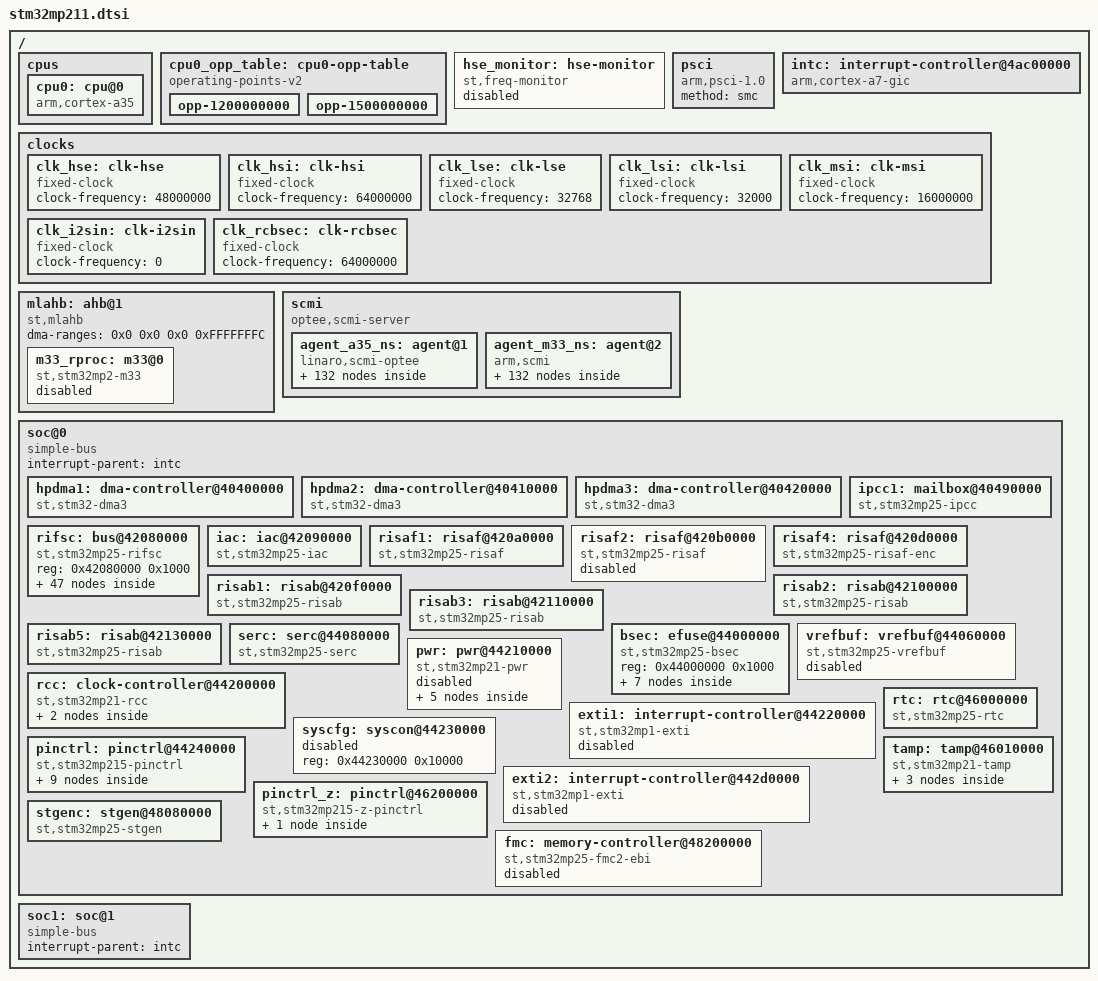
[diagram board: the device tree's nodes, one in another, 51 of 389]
// SPDX-License-Identifier: (GPL-2.0-only OR BSD-3-Clause)
/*
 * Copyright (C) 2024, STMicroelectronics - All Rights Reserved
 * Author: Alexandre Torgue <alexandre.torgue@foss.st.com> for STMicroelectronics.
 */
#include <dt-bindings/clock/st,stm32mp21-rcc.h>
#include <dt-bindings/gpio/gpio.h>
#include <dt-bindings/interrupt-controller/arm-gic.h>
#include <dt-bindings/regulator/st,stm32mp21-regulator.h>
#include <dt-bindings/reset/st,stm32mp21-rcc.h>
#include <dt-bindings/scmi/scmi-clock.h>
#include <dt-bindings/soc/stm32mp21-rifsc.h>
#include <dt-bindings/soc/stm32mp25-rif.h>
#include <dt-bindings/soc/stm32mp25-risab.h>
#include <dt-bindings/soc/stm32mp25-risaf.h>

/ {
	#address-cells = <2>;
	#size-cells = <2>;

	cpus {
		#address-cells = <1>;
		#size-cells = <0>;

		cpu0: cpu@0 {
			compatible = "arm,cortex-a35";
			device_type = "cpu";
			reg = <0>;
			enable-method = "psci";
			operating-points-v2 = <&cpu0_opp_table>;
			clocks = <&rcc CK_CPU1>;
		};
	};

	cpu0_opp_table: cpu0-opp-table {
		compatible = "operating-points-v2";

		opp-1200000000 {
			opp-hz = /bits/ 64 <1200000000>;
			opp-microvolt = <800000>;
			opp-supported-hw = <0x3>;
			st,opp-default;
		};

		opp-1500000000 {
			opp-hz = /bits/ 64 <1500000000>;
			opp-microvolt = <910000>;
			opp-supported-hw = <0x2>;
		};
	};

	hse_monitor: hse-monitor {
		compatible = "st,freq-monitor";
		counter = <&lptimer1 1 5 1 1>;
		clocks = <&rcc HSE_CK>, <&rcc HSI_CK>;
		clock-names = "hse", "hsi";
		status = "disabled";
	};

	psci {
		compatible = "arm,psci-1.0";
		method = "smc";
	};

	intc: interrupt-controller@4ac00000 {
		compatible = "arm,cortex-a7-gic";
		#interrupt-cells = <3>;
		interrupt-controller;
		reg = <0x0 0x4ac10000 0x0 0x1000>,
		      <0x0 0x4ac20000 0x0 0x2000>,
		      <0x0 0x4ac40000 0x0 0x2000>,
		      <0x0 0x4ac60000 0x0 0x2000>;
		#address-cells = <1>;
	};

	clocks {
		clk_hse: clk-hse {
			#clock-cells = <0>;
			compatible = "fixed-clock";
			clock-frequency = <48000000>;
		};

		clk_hsi: clk-hsi {
			#clock-cells = <0>;
			compatible = "fixed-clock";
			clock-frequency = <64000000>;
		};

		clk_lse: clk-lse {
			#clock-cells = <0>;
			compatible = "fixed-clock";
			clock-frequency = <32768>;
		};

		clk_lsi: clk-lsi {
			#clock-cells = <0>;
			compatible = "fixed-clock";
			clock-frequency = <32000>;
		};

		clk_msi: clk-msi {
			#clock-cells = <0>;
			compatible = "fixed-clock";
			clock-frequency = <16000000>;
		};

		clk_i2sin: clk-i2sin {
			#clock-cells = <0>;
			compatible = "fixed-clock";
			clock-frequency = <0>;
		};

		clk_rcbsec: clk-rcbsec {
			#clock-cells = <0>;
			compatible = "fixed-clock";
			clock-frequency = <64000000>;
		};
	};

	mlahb: ahb@1 {
		compatible = "st,mlahb", "simple-bus";
		#address-cells = <1>;
		#size-cells = <1>;
		ranges = <0x0 0x0 0x0 0xFFFFFFFC>;
		dma-ranges = <0x0 0x0 0x0 0xFFFFFFFC>;

		m33_rproc: m33@0 {
			compatible = "st,stm32mp2-m33";
			#reset-cells = <1>;
			reg = <0 0>;
			resets = <&rcc C2_R>,
				 <&rcc C2_HOLDBOOT_R>;
			reset-names = "mcu_rst", "hold_boot";
			status = "disabled";
		};
	};

	scmi: scmi {
		compatible = "optee,scmi-server";
		#address-cells = <1>;
		#size-cells = <0>;

		agent_a35_ns: agent@1 {
			reg = <1>;
			compatible = "linaro,scmi-optee";
			scmi-channel-id = <0>;
			#address-cells = <1>;
			#size-cells = <0>;

			scmi_clock: protocol@14 {
				reg = <0x14>;

				clocks {
					#address-cells = <1>;
					#size-cells = <0>;
					#clock-cells = <1>;

					clock@0 {
						reg = <CK_SCMI_ICN_HS_MCU>;
						clocks = <&rcc CK_ICN_HS_MCU>;
						domain-name = "ck_icn_hs_mcu";
						flags = <SCMI_CLOCK_DEFAULT_ENABLED>;
					};

					clock@1 {
						reg = <CK_SCMI_ICN_SDMMC>;
						clocks = <&rcc CK_ICN_SDMMC>;
						domain-name = "ck_icn_sdmmc";
						flags = <SCMI_CLOCK_DEFAULT_ENABLED>;
					};

					clock@2 {
						reg = <CK_SCMI_ICN_DDR>;
						clocks = <&rcc CK_ICN_DDR>;
						domain-name = "ck_icn_ddr";
						flags = <SCMI_CLOCK_DEFAULT_ENABLED>;
					};

					clock@3 {
						reg = <CK_SCMI_ICN_DISPLAY>;
						clocks = <&rcc CK_ICN_DISPLAY>;
						domain-name = "ck_icn_display";
						flags = <SCMI_CLOCK_DEFAULT_ENABLED>;
					};

					clock@4 {
						reg = <CK_SCMI_ICN_HSL>;
						clocks = <&rcc CK_ICN_HSL>;
						domain-name = "ck_icn_hsl";
						flags = <SCMI_CLOCK_DEFAULT_ENABLED>;
					};

					clock@5 {
						reg = <CK_SCMI_ICN_NIC>;
						clocks = <&rcc CK_ICN_NIC>;
						domain-name = "ck_icn_nic";
						flags = <SCMI_CLOCK_DEFAULT_ENABLED>;
					};

					clock@7 {
						reg = <CK_SCMI_FLEXGEN_07>;
						clocks = <&rcc CK_FLEXGEN_07>;
						domain-name = "ck_flexgen_07";
						flags = <SCMI_CLOCK_DEFAULT_ENABLED>;
					};

					clock@8 {
						reg = <CK_SCMI_FLEXGEN_08>;
						clocks = <&rcc CK_FLEXGEN_08>;
						domain-name = "ck_flexgen_08";
						flags = <SCMI_CLOCK_DEFAULT_ENABLED>;
					};

					clock@9 {
						reg = <CK_SCMI_FLEXGEN_09>;
						clocks = <&rcc CK_FLEXGEN_09>;
						domain-name = "ck_flexgen_09";
						flags = <SCMI_CLOCK_DEFAULT_ENABLED>;
					};

					clock@a {
						reg = <CK_SCMI_FLEXGEN_10>;
						clocks = <&rcc CK_FLEXGEN_10>;
						domain-name = "ck_flexgen_10";
						flags = <(SCMI_CLOCK_DEFAULT_ENABLED |
							  SCMI_CLOCK_ALLOW_SET_RATE)>;
					};

					clock@b {
						reg = <CK_SCMI_FLEXGEN_11>;
						clocks = <&rcc CK_FLEXGEN_11>;
						domain-name = "ck_flexgen_11";
						flags = <(SCMI_CLOCK_DEFAULT_ENABLED |
							  SCMI_CLOCK_ALLOW_SET_RATE)>;
					};

					clock@c {
						reg = <CK_SCMI_FLEXGEN_12>;
						clocks = <&rcc CK_FLEXGEN_12>;
						domain-name = "ck_flexgen_12";
						flags = <SCMI_CLOCK_DEFAULT_ENABLED>;
					};

					clock@d {
						reg = <CK_SCMI_FLEXGEN_13>;
						clocks = <&rcc CK_FLEXGEN_13>;
						domain-name = "ck_flexgen_13";
						flags = <SCMI_CLOCK_DEFAULT_ENABLED>;
					};

					clock@e {
						reg = <CK_SCMI_FLEXGEN_14>;
						clocks = <&rcc CK_FLEXGEN_14>;
						domain-name = "ck_flexgen_14";
						flags = <SCMI_CLOCK_DEFAULT_ENABLED>;
					};

					clock@f {
						reg = <CK_SCMI_FLEXGEN_15>;
						clocks = <&rcc CK_FLEXGEN_15>;
						domain-name = "ck_flexgen_15";
						flags = <SCMI_CLOCK_DEFAULT_ENABLED>;
					};

					clock@10 {
						reg = <CK_SCMI_FLEXGEN_16>;
						clocks = <&rcc CK_FLEXGEN_16>;
						domain-name = "ck_flexgen_16";
						flags = <(SCMI_CLOCK_DEFAULT_ENABLED |
							  SCMI_CLOCK_ALLOW_SET_RATE)>;
					};

					clock@11 {
						reg = <CK_SCMI_FLEXGEN_17>;
						clocks = <&rcc CK_FLEXGEN_17>;
						domain-name = "ck_flexgen_17";
						flags = <SCMI_CLOCK_DEFAULT_ENABLED>;
					};

					clock@12 {
						reg = <CK_SCMI_FLEXGEN_18>;
						clocks = <&rcc CK_FLEXGEN_18>;
						domain-name = "ck_flexgen_18";
						flags = <SCMI_CLOCK_DEFAULT_ENABLED>;
					};

					clock@13 {
						reg = <CK_SCMI_FLEXGEN_19>;
						clocks = <&rcc CK_FLEXGEN_19>;
						domain-name = "ck_flexgen_19";
						flags = <SCMI_CLOCK_DEFAULT_ENABLED>;
					};

					clock@14 {
						reg = <CK_SCMI_FLEXGEN_20>;
						clocks = <&rcc CK_FLEXGEN_20>;
						domain-name = "ck_flexgen_20";
						flags = <SCMI_CLOCK_DEFAULT_ENABLED>;
					};

					clock@15 {
						reg = <CK_SCMI_FLEXGEN_21>;
						clocks = <&rcc CK_FLEXGEN_21>;
						domain-name = "ck_flexgen_21";
						flags = <SCMI_CLOCK_DEFAULT_ENABLED>;
					};

					clock@16 {
						reg = <CK_SCMI_FLEXGEN_22>;
						clocks = <&rcc CK_FLEXGEN_22>;
						domain-name = "ck_flexgen_22";
						flags = <(SCMI_CLOCK_DEFAULT_ENABLED |
							  SCMI_CLOCK_ALLOW_SET_RATE)>;
					};

					clock@17 {
						reg = <CK_SCMI_FLEXGEN_23>;
						clocks = <&rcc CK_FLEXGEN_23>;
						domain-name = "ck_flexgen_23";
						flags = <(SCMI_CLOCK_DEFAULT_ENABLED |
							  SCMI_CLOCK_ALLOW_SET_RATE)>;
					};

					clock@18 {
						reg = <CK_SCMI_FLEXGEN_24>;
						clocks = <&rcc CK_FLEXGEN_24>;
						domain-name = "ck_flexgen_24";
						flags = <(SCMI_CLOCK_DEFAULT_ENABLED |
							  SCMI_CLOCK_ALLOW_SET_RATE)>;
					};

					clock@19 {
						reg = <CK_SCMI_FLEXGEN_25>;
						clocks = <&rcc CK_FLEXGEN_25>;
						domain-name = "ck_flexgen_25";
						flags = <(SCMI_CLOCK_DEFAULT_ENABLED |
							  SCMI_CLOCK_ALLOW_SET_RATE)>;
					};

					clock@1a {
						reg = <CK_SCMI_FLEXGEN_26>;
						clocks = <&rcc CK_FLEXGEN_26>;
						domain-name = "ck_flexgen_26";
						flags = <SCMI_CLOCK_DEFAULT_ENABLED>;
					};

					clock@1b {
						reg = <CK_SCMI_FLEXGEN_27>;
						clocks = <&rcc CK_FLEXGEN_27>;
						domain-name = "ck_flexgen_27";
						flags = <(SCMI_CLOCK_DEFAULT_ENABLED |
							  SCMI_CLOCK_ALLOW_SET_RATE)>;
					};

					clock@1c {
						reg = <CK_SCMI_FLEXGEN_28>;
						clocks = <&rcc CK_FLEXGEN_28>;
						domain-name = "ck_flexgen_28";
						flags = <SCMI_CLOCK_DEFAULT_ENABLED>;
					};

					clock@1d {
						reg = <CK_SCMI_FLEXGEN_29>;
						clocks = <&rcc CK_FLEXGEN_29>;
						domain-name = "ck_flexgen_29";
						flags = <SCMI_CLOCK_DEFAULT_ENABLED>;
					};

					clock@1e {
						reg = <CK_SCMI_FLEXGEN_30>;
						clocks = <&rcc CK_FLEXGEN_30>;
						domain-name = "ck_flexgen_30";
						flags = <SCMI_CLOCK_DEFAULT_ENABLED>;
					};

					clock@1f {
						reg = <CK_SCMI_FLEXGEN_31>;
						clocks = <&rcc CK_FLEXGEN_31>;
						domain-name = "ck_flexgen_31";
						flags = <SCMI_CLOCK_DEFAULT_ENABLED>;
					};

					clock@20 {
						reg = <CK_SCMI_FLEXGEN_32>;
						clocks = <&rcc CK_FLEXGEN_32>;
						domain-name = "ck_flexgen_32";
						flags = <SCMI_CLOCK_DEFAULT_ENABLED>;
					};

					clock@21 {
						reg = <CK_SCMI_FLEXGEN_33>;
						clocks = <&rcc CK_FLEXGEN_33>;
						domain-name = "ck_flexgen_33";
						flags = <SCMI_CLOCK_DEFAULT_ENABLED>;
					};

					clock@22 {
						reg = <CK_SCMI_FLEXGEN_34>;
						clocks = <&rcc CK_FLEXGEN_34>;
						domain-name = "ck_flexgen_34";
						flags = <SCMI_CLOCK_DEFAULT_ENABLED>;
					};

					clock@23 {
						reg = <CK_SCMI_FLEXGEN_35>;
						clocks = <&rcc CK_FLEXGEN_35>;
						domain-name = "ck_flexgen_35";
						flags = <SCMI_CLOCK_DEFAULT_ENABLED>;
					};

					clock@24 {
						reg = <CK_SCMI_FLEXGEN_36>;
						clocks = <&rcc CK_FLEXGEN_36>;
						domain-name = "ck_flexgen_36";
						flags = <SCMI_CLOCK_DEFAULT_ENABLED>;
					};

					clock@25 {
						reg = <CK_SCMI_FLEXGEN_37>;
						clocks = <&rcc CK_FLEXGEN_37>;
						domain-name = "ck_flexgen_37";
						flags = <SCMI_CLOCK_DEFAULT_ENABLED>;
					};

					clock@26 {
						reg = <CK_SCMI_FLEXGEN_38>;
						clocks = <&rcc CK_FLEXGEN_38>;
						domain-name = "ck_flexgen_38";
						flags = <SCMI_CLOCK_DEFAULT_ENABLED>;
					};

					clock@27 {
						reg = <CK_SCMI_FLEXGEN_39>;
						clocks = <&rcc CK_FLEXGEN_39>;
						domain-name = "ck_flexgen_39";
						flags = <SCMI_CLOCK_DEFAULT_ENABLED>;
					};

					clock@28 {
						reg = <CK_SCMI_FLEXGEN_40>;
						clocks = <&rcc CK_FLEXGEN_40>;
						domain-name = "ck_flexgen_40";
						flags = <SCMI_CLOCK_DEFAULT_ENABLED>;
					};

					clock@29 {
						reg = <CK_SCMI_FLEXGEN_41>;
						clocks = <&rcc CK_FLEXGEN_41>;
						domain-name = "ck_flexgen_41";
						flags = <SCMI_CLOCK_DEFAULT_ENABLED>;
					};

					clock@2a {
						reg = <CK_SCMI_FLEXGEN_42>;
						clocks = <&rcc CK_FLEXGEN_42>;
						domain-name = "ck_flexgen_42";
						flags = <SCMI_CLOCK_DEFAULT_ENABLED>;
					};

					clock@2b {
						reg = <CK_SCMI_FLEXGEN_43>;
						clocks = <&rcc CK_FLEXGEN_43>;
						domain-name = "ck_flexgen_43";
						flags = <SCMI_CLOCK_DEFAULT_ENABLED>;
					};

					clock@2c {
						reg = <CK_SCMI_FLEXGEN_44>;
						clocks = <&rcc CK_FLEXGEN_44>;
						domain-name = "ck_flexgen_44";
						flags = <SCMI_CLOCK_DEFAULT_ENABLED>;
					};

					clock@2d {
						reg = <CK_SCMI_FLEXGEN_45>;
						clocks = <&rcc CK_FLEXGEN_45>;
						domain-name = "ck_flexgen_45";
						flags = <SCMI_CLOCK_DEFAULT_ENABLED>;
					};

					clock@2e {
						reg = <CK_SCMI_FLEXGEN_46>;
						clocks = <&rcc CK_FLEXGEN_46>;
						domain-name = "ck_flexgen_46";
						flags = <SCMI_CLOCK_DEFAULT_ENABLED>;
					};

					clock@2f {
						reg = <CK_SCMI_FLEXGEN_47>;
						clocks = <&rcc CK_FLEXGEN_47>;
						domain-name = "ck_flexgen_47";
						flags = <SCMI_CLOCK_DEFAULT_ENABLED>;
					};

					clock@30 {
						reg = <CK_SCMI_FLEXGEN_48>;
						clocks = <&rcc CK_FLEXGEN_48>;
						domain-name = "ck_flexgen_48";
						flags = <SCMI_CLOCK_DEFAULT_ENABLED>;
					};

					clock@31 {
						reg = <CK_SCMI_FLEXGEN_49>;
						clocks = <&rcc CK_FLEXGEN_49>;
						domain-name = "ck_flexgen_49";
						flags = <SCMI_CLOCK_DEFAULT_ENABLED>;
					};

					clock@32 {
						reg = <CK_SCMI_FLEXGEN_50>;
						clocks = <&rcc CK_FLEXGEN_50>;
						domain-name = "ck_flexgen_50";
						flags = <SCMI_CLOCK_DEFAULT_ENABLED>;
					};

					clock@33 {
						reg = <CK_SCMI_FLEXGEN_51>;
						clocks = <&rcc CK_FLEXGEN_51>;
						domain-name = "ck_flexgen_51";
						flags = <SCMI_CLOCK_DEFAULT_ENABLED>;
					};

					clock@34 {
						reg = <CK_SCMI_FLEXGEN_52>;
						clocks = <&rcc CK_FLEXGEN_52>;
						domain-name = "ck_flexgen_52";
						flags = <SCMI_CLOCK_DEFAULT_ENABLED>;
					};

					clock@35 {
						reg = <CK_SCMI_FLEXGEN_53>;
						clocks = <&rcc CK_FLEXGEN_53>;
						domain-name = "ck_flexgen_53";
						flags = <SCMI_CLOCK_DEFAULT_ENABLED>;
					};

					clock@36 {
						reg = <CK_SCMI_FLEXGEN_54>;
						clocks = <&rcc CK_FLEXGEN_54>;
						domain-name = "ck_flexgen_54";
						flags = <SCMI_CLOCK_DEFAULT_ENABLED>;
					};

					clock@37 {
						reg = <CK_SCMI_FLEXGEN_55>;
						clocks = <&rcc CK_FLEXGEN_55>;
						domain-name = "ck_flexgen_55";
						flags = <SCMI_CLOCK_DEFAULT_ENABLED>;
					};

					clock@38 {
						reg = <CK_SCMI_FLEXGEN_56>;
						clocks = <&rcc CK_FLEXGEN_56>;
						domain-name = "ck_flexgen_56";
						flags = <SCMI_CLOCK_DEFAULT_ENABLED>;
					};

					clock@39 {
						reg = <CK_SCMI_FLEXGEN_57>;
						clocks = <&rcc CK_FLEXGEN_57>;
						domain-name = "ck_flexgen_57";
						flags = <SCMI_CLOCK_DEFAULT_ENABLED>;
					};

					clock@3a {
						reg = <CK_SCMI_FLEXGEN_58>;
						clocks = <&rcc CK_FLEXGEN_58>;
						domain-name = "ck_flexgen_58";
						flags = <SCMI_CLOCK_DEFAULT_ENABLED>;
					};

					clock@3b {
						reg = <CK_SCMI_FLEXGEN_59>;
						clocks = <&rcc CK_FLEXGEN_59>;
						domain-name = "ck_flexgen_59";
						flags = <SCMI_CLOCK_DEFAULT_ENABLED>;
					};

					clock@3c {
						reg = <CK_SCMI_FLEXGEN_60>;
						clocks = <&rcc CK_FLEXGEN_60>;
						domain-name = "ck_flexgen_60";
						flags = <SCMI_CLOCK_DEFAULT_ENABLED>;
					};

					clock@3d {
						reg = <CK_SCMI_FLEXGEN_61>;
						clocks = <&rcc CK_FLEXGEN_61>;
						domain-name = "ck_flexgen_61";
						flags = <SCMI_CLOCK_DEFAULT_ENABLED>;
					};

					clock@3e {
						reg = <CK_SCMI_FLEXGEN_62>;
						clocks = <&rcc CK_FLEXGEN_62>;
						domain-name = "ck_flexgen_62";
						flags = <SCMI_CLOCK_DEFAULT_ENABLED>;
					};

					clock@3f {
						reg = <CK_SCMI_FLEXGEN_63>;
						clocks = <&rcc CK_FLEXGEN_63>;
						domain-name = "ck_flexgen_63";
						flags = <SCMI_CLOCK_DEFAULT_ENABLED>;
					};

					clock@40 {
						reg = <CK_SCMI_ICN_LS_MCU>;
						clocks = <&rcc CK_ICN_LS_MCU>;
						domain-name = "ck_icn_ls_mcu";
						flags = <SCMI_CLOCK_DEFAULT_ENABLED>;
					};

					clock@41 {
						reg = <CK_SCMI_HSE>;
						clocks = <&rcc HSE_CK>;
						domain-name = "hse_ck";
						flags = <SCMI_CLOCK_DEFAULT_ENABLED>;
					};

					clock@42 {
						reg = <CK_SCMI_LSE>;
						clocks = <&rcc LSE_CK>;
						domain-name = "lse_ck";
						flags = <SCMI_CLOCK_DEFAULT_ENABLED>;
					};

					clock@43 {
						reg = <CK_SCMI_HSI>;
						clocks = <&rcc HSI_CK>;
						domain-name = "hsi_ck";
						flags = <SCMI_CLOCK_DEFAULT_ENABLED>;
					};

					clock@44 {
						reg = <CK_SCMI_LSI>;
						clocks = <&rcc LSI_CK>;
						domain-name = "lsi_ck";
						flags = <SCMI_CLOCK_DEFAULT_ENABLED>;
					};

					clock@45 {
						reg = <CK_SCMI_MSI>;
						clocks = <&rcc MSI_CK>;
						domain-name = "msi_ck";
						flags = <SCMI_CLOCK_DEFAULT_ENABLED>;
					};

					clock@46 {
						reg = <CK_SCMI_HSE_DIV2>;
						clocks = <&rcc HSE_DIV2_CK>;
						domain-name = "hse_div2_ck";
					};

					clock@47 {
						reg = <CK_SCMI_CPU1>;
						clocks = <&rcc CK_CPU1>;
						domain-name = "ck_cpu1";
						flags = <SCMI_CLOCK_DEFAULT_ENABLED>;
					};

					clock@48 {
						reg = <CK_SCMI_SYSCPU1>;
						clocks = <&rcc CK_BUS_SYSCPU1>;
						domain-name = "ck_bus_syscpu1";
						flags = <SCMI_CLOCK_DEFAULT_ENABLED>;
					};

					clock@49 {
						reg = <CK_SCMI_PLL2>;
						clocks = <&rcc PLL2_CK>;
						domain-name = "ck_pll2";
						flags = <SCMI_CLOCK_DEFAULT_ENABLED>;
					};

					clock@4a {
						reg = <CK_SCMI_RTC>;
						clocks = <&rcc CK_BUS_RTC>;
						domain-name = "ck_bus_rtc";
						flags = <SCMI_CLOCK_DEFAULT_ENABLED>;
					};

					clock@4b {
						reg = <CK_SCMI_RTCCK>;
						clocks = <&rcc RTC_CK>;
						domain-name = "rtc_ck";
						flags = <SCMI_CLOCK_DEFAULT_ENABLED>;
					};

					clock@4c {
						reg = <CK_SCMI_ICN_APB1>;
						clocks = <&rcc CK_ICN_APB1>;
						domain-name = "ck_icn_apb1";
						flags = <SCMI_CLOCK_DEFAULT_ENABLED>;
					};

					clock@4d {
						reg = <CK_SCMI_ICN_APB2>;
						clocks = <&rcc CK_ICN_APB2>;
						domain-name = "ck_icn_apb2";
						flags = <SCMI_CLOCK_DEFAULT_ENABLED>;
					};

					clock@4e {
						reg = <CK_SCMI_ICN_APB3>;
						clocks = <&rcc CK_ICN_APB3>;
						domain-name = "ck_icn_apb3";
						flags = <SCMI_CLOCK_DEFAULT_ENABLED>;
					};

					clock@4f {
						reg = <CK_SCMI_ICN_APB4>;
						clocks = <&rcc CK_ICN_APB4>;
						domain-name = "ck_icn_apb4";
						flags = <SCMI_CLOCK_DEFAULT_ENABLED>;
					};

					clock@50 {
						reg = <CK_SCMI_ICN_APB5>;
						clocks = <&rcc CK_ICN_APB5>;
						domain-name = "ck_icn_apb5";
						flags = <SCMI_CLOCK_DEFAULT_ENABLED>;
					};

					clock@51 {
						reg = <CK_SCMI_ICN_APBDBG>;
						clocks = <&rcc CK_ICN_APBDBG>;
						domain-name = "ck_icn_apbdbg";
						flags = <SCMI_CLOCK_DEFAULT_ENABLED>;
					};

					clock@52 {
						reg = <CK_SCMI_TIMG1>;
						clocks = <&rcc TIMG1_CK>;
						domain-name = "timg1_ck";
						flags = <SCMI_CLOCK_DEFAULT_ENABLED>;
					};

					clock@53 {
						reg = <CK_SCMI_TIMG2>;
						clocks = <&rcc TIMG2_CK>;
						domain-name = "timg2_ck";
						flags = <SCMI_CLOCK_DEFAULT_ENABLED>;
					};

					clock@54 {
						reg = <CK_SCMI_BKPSRAM>;
						clocks = <&rcc CK_BUS_BKPSRAM>;
						domain-name = "ck_bus_bkpsram";
						flags = <SCMI_CLOCK_DEFAULT_ENABLED>;
					};

					clock@55 {
						reg = <CK_SCMI_BSEC>;
						clocks = <&rcc CK_BUS_BSEC>;
						domain-name = "ck_bus_bsec";
						flags = <SCMI_CLOCK_DEFAULT_ENABLED>;
					};

					clock@56 {
						reg = <CK_SCMI_BUS_ETR>;
						clocks = <&rcc CK_BUS_ETR>;
						domain-name = "ck_icn_p_etr";
						flags = <SCMI_CLOCK_DEFAULT_ENABLED>;
					};

					clock@57 {
						reg = <CK_SCMI_FMC>;
						clocks = <&rcc CK_KER_FMC>;
						domain-name = "ck_ker_fmc";
						flags = <SCMI_CLOCK_DEFAULT_ENABLED>;
					};

					clock@58 {
						reg = <CK_SCMI_GPIOA>;
						clocks = <&rcc CK_BUS_GPIOA>;
						domain-name = "ck_bus_gpioa";
						flags = <SCMI_CLOCK_DEFAULT_ENABLED>;
					};

					clock@59 {
						reg = <CK_SCMI_GPIOB>;
						clocks = <&rcc CK_BUS_GPIOB>;
						domain-name = "ck_bus_gpiob";
						flags = <SCMI_CLOCK_DEFAULT_ENABLED>;
					};

					clock@5a {
						reg = <CK_SCMI_GPIOC>;
						clocks = <&rcc CK_BUS_GPIOC>;
						domain-name = "ck_bus_gpioc";
						flags = <SCMI_CLOCK_DEFAULT_ENABLED>;
					};

					clock@5b {
						reg = <CK_SCMI_GPIOD>;
						clocks = <&rcc CK_BUS_GPIOD>;
						domain-name = "ck_bus_gpiod";
						flags = <SCMI_CLOCK_DEFAULT_ENABLED>;
					};

					clock@5c {
						reg = <CK_SCMI_GPIOE>;
						clocks = <&rcc CK_BUS_GPIOE>;
						domain-name = "ck_bus_gpioe";
						flags = <SCMI_CLOCK_DEFAULT_ENABLED>;
					};

					clock@5d {
						reg = <CK_SCMI_GPIOF>;
						clocks = <&rcc CK_BUS_GPIOF>;
						domain-name = "ck_bus_gpiof";
						flags = <SCMI_CLOCK_DEFAULT_ENABLED>;
					};

					clock@5e {
						reg = <CK_SCMI_GPIOG>;
						clocks = <&rcc CK_BUS_GPIOG>;
						domain-name = "ck_bus_gpiog";
						flags = <SCMI_CLOCK_DEFAULT_ENABLED>;
					};

					clock@5f {
						reg = <CK_SCMI_GPIOH>;
						clocks = <&rcc CK_BUS_GPIOH>;
						domain-name = "ck_bus_gpioh";
						flags = <SCMI_CLOCK_DEFAULT_ENABLED>;
					};

					clock@60 {
						reg = <CK_SCMI_GPIOI>;
						clocks = <&rcc CK_BUS_GPIOI>;
						domain-name = "ck_bus_gpioi";
						flags = <SCMI_CLOCK_DEFAULT_ENABLED>;
					};

					clock@61 {
						reg = <CK_SCMI_GPIOZ>;
						clocks = <&rcc CK_BUS_GPIOZ>;
						domain-name = "ck_bus_gpioz";
						flags = <SCMI_CLOCK_DEFAULT_ENABLED>;
					};

					clock@62 {
						reg = <CK_SCMI_HPDMA1>;
						clocks = <&rcc CK_BUS_HPDMA1>;
						domain-name = "ck_bus_hpdma1";
						flags = <SCMI_CLOCK_DEFAULT_ENABLED>;
					};

					clock@63 {
						reg = <CK_SCMI_HPDMA2>;
						clocks = <&rcc CK_BUS_HPDMA2>;
						domain-name = "ck_bus_hpdma2";
						flags = <SCMI_CLOCK_DEFAULT_ENABLED>;
					};

					clock@64 {
						reg = <CK_SCMI_HPDMA3>;
						clocks = <&rcc CK_BUS_HPDMA3>;
						domain-name = "ck_bus_hpdma3";
						flags = <SCMI_CLOCK_DEFAULT_ENABLED>;
					};

					clock@65 {
						reg = <CK_SCMI_IPCC1>;
						clocks = <&rcc CK_BUS_IPCC1>;
						domain-name = "ck_bus_ipcc1";
						flags = <SCMI_CLOCK_DEFAULT_ENABLED>;
					};

					clock@66 {
						reg = <CK_SCMI_RETRAM>;
						clocks = <&rcc CK_BUS_RETRAM>;
						domain-name = "ck_bus_retram";
						flags = <SCMI_CLOCK_DEFAULT_ENABLED>;
					};

					clock@67 {
						reg = <CK_SCMI_SRAM1>;
						clocks = <&rcc CK_BUS_SRAM1>;
						domain-name = "ck_bus_sram1";
						flags = <SCMI_CLOCK_DEFAULT_ENABLED>;
					};

					clock@68 {
						reg = <CK_SCMI_SYSRAM>;
						clocks = <&rcc CK_BUS_SYSRAM>;
						domain-name = "ck_icn_s_sysram";
						flags = <SCMI_CLOCK_DEFAULT_ENABLED>;
					};

					clock@69 {
						reg = <CK_SCMI_OSPI1>;
						clocks = <&rcc CK_KER_OSPI1>;
						domain-name = "ck_ker_ospi1";
						flags = <SCMI_CLOCK_DEFAULT_ENABLED>;
					};

					clock@6a {
						reg = <CK_SCMI_TPIU>;
						clocks = <&rcc CK_KER_TPIU>;
						domain-name = "ck_ker_tpiu";
						flags = <SCMI_CLOCK_DEFAULT_ENABLED>;
					};

					clock@6b {
						reg = <CK_SCMI_SYSDBG>;
						clocks = <&rcc CK_SYSDBG>;
						domain-name = "ck_sys_dbg";
						flags = <SCMI_CLOCK_DEFAULT_ENABLED>;
					};

					clock@6c {
						reg = <CK_SCMI_SYSATB>;
						clocks = <&rcc CK_BUS_SYSATB>;
						domain-name = "ck_sys_atb";
						flags = <SCMI_CLOCK_DEFAULT_ENABLED>;
					};

					clock@6d {
						reg = <CK_SCMI_TSDBG>;
						clocks = <&rcc CK_KER_TSDBG>;
						domain-name = "ck_ker_tsdbg";
						flags = <SCMI_CLOCK_DEFAULT_ENABLED>;
					};

					clock@6e {
						reg = <CK_SCMI_BUS_STM>;
						clocks = <&rcc CK_BUS_STM>;
						domain-name = "ck_icn_p_stm";
						flags = <SCMI_CLOCK_DEFAULT_ENABLED>;
					};

					clock@6f {
						reg = <CK_SCMI_KER_STM>;
						clocks = <&rcc CK_KER_STM>;
						domain-name = "ck_icn_s_stm";
						flags = <SCMI_CLOCK_DEFAULT_ENABLED>;
					};

					clock@70 {
						reg = <CK_SCMI_KER_ETR>;
						clocks = <&rcc CK_KER_ETR>;
						domain-name = "ck_icn_m_etr";
						flags = <SCMI_CLOCK_DEFAULT_ENABLED>;
					};

					clock@71 {
						reg = <CK_SCMI_HSI_KER_CK>;
						domain-name = "hsi_ker_ck";
						clocks = <&rcc HSI_KER_CK>;
						flags = <SCMI_CLOCK_DEFAULT_ENABLED>;
					};

					clock@72 {
						reg = <CK_SCMI_HSE_KER_CK>;
						domain-name = "hse_ker_ck";
						clocks = <&rcc HSE_KER_CK>;
						flags = <SCMI_CLOCK_DEFAULT_ENABLED>;
					};

					clock@73 {
						reg = <CK_SCMI_MSI_KER_CK>;
						domain-name = "msi_ker_ck";
						clocks = <&rcc MSI_KER_CK>;
						flags = <SCMI_CLOCK_DEFAULT_ENABLED>;
					};
				};
			};

			scmi_reset: protocol@16 {
				reg = <0x16>;

				resets {
					#address-cells = <1>;
					#size-cells = <0>;
					#reset-cells = <1>;

					reset@0 {
						reg = <RST_SCMI_C1_R>;
						domain-name = "c1";
						resets = <&rcc C1_R>;
					};

					reset@1 {
						reg = <RST_SCMI_C2_R>;
						domain-name = "c2";
						resets = <&m33_rproc 0>;
					};

					reset@2 {
						reg = <RST_SCMI_C1_HOLDBOOT_R>;
						domain-name = "c1_holdboot";
						resets = <&rcc C1_HOLDBOOT_R>;
					};

					reset@3 {
						reg = <RST_SCMI_C2_HOLDBOOT_R>;
						domain-name = "c2_holdboot";
						resets = <&m33_rproc 1>;
					};

					reset@4 {
						reg = <RST_SCMI_FMC>;
						domain-name = "fmc";
						resets = <&rcc FMC_R>;
					};

					reset@5 {
						reg = <RST_SCMI_OSPI1>;
						domain-name = "ospi1";
						resets = <&rcc OSPI1_R>;
					};

					reset@6 {
						reg = <RST_SCMI_OSPI1DLL>;
						domain-name = "ospi1_ddl";
						resets = <&rcc OSPI1DLL_R>;
					};
				};
			};

			scmi_regulator: protocol@17 {
				reg = <0x17>;

				scmi_regu: regulators {
					#address-cells = <1>;
					#size-cells = <0>;

					voltd-vddio1 {
						reg = <VOLTD_SCMI_VDDIO1>;
						voltd-supply = <&vddio1>;
					};

					voltd-vddio2 {
						reg = <VOLTD_SCMI_VDDIO2>;
						voltd-supply = <&vddio2>;
					};

					voltd-vddio3 {
						reg = <VOLTD_SCMI_VDDIO3>;
						voltd-supply = <&vddio3>;
					};

					voltd-vdda18adc {
						reg = <VOLTD_SCMI_ADC>;
						voltd-supply = <&vdda18adc>;
					};
				};
			};
		};

		agent_m33_ns: agent@2 {
			reg = <2>;
			compatible = "arm,scmi";
			scmi-channel-id = <0>;
			mbox-names = "scmi_cm33";
			mboxes = <&ipcc1 RIF_IPCC_CPU1_CHANNEL(16)>;
			shmem = <&ipc_shmem>;
			#address-cells = <1>;
			#size-cells = <0>;

			scmi_clock_m33: protocol@14 {
				reg = <0x14>;

				clocks {
					#address-cells = <1>;
					#size-cells = <0>;
					#clock-cells = <1>;

					clock@0 {
						reg = <CK_SCMI_ICN_HS_MCU>;
						clocks = <&rcc CK_ICN_HS_MCU>;
						domain-name = "ck_icn_hs_mcu";
						flags = <SCMI_CLOCK_DEFAULT_ENABLED>;
					};

					clock@1 {
						reg = <CK_SCMI_ICN_SDMMC>;
						clocks = <&rcc CK_ICN_SDMMC>;
						domain-name = "ck_icn_sdmmc";
						flags = <SCMI_CLOCK_DEFAULT_ENABLED>;
					};

					clock@2 {
						reg = <CK_SCMI_ICN_DDR>;
						clocks = <&rcc CK_ICN_DDR>;
						domain-name = "ck_icn_ddr";
						flags = <SCMI_CLOCK_DEFAULT_ENABLED>;
					};

					clock@3 {
						reg = <CK_SCMI_ICN_DISPLAY>;
						clocks = <&rcc CK_ICN_DISPLAY>;
						domain-name = "ck_icn_display";
						flags = <SCMI_CLOCK_DEFAULT_ENABLED>;
					};

					clock@4 {
						reg = <CK_SCMI_ICN_HSL>;
						clocks = <&rcc CK_ICN_HSL>;
						domain-name = "ck_icn_hsl";
						flags = <SCMI_CLOCK_DEFAULT_ENABLED>;
					};

					clock@5 {
						reg = <CK_SCMI_ICN_NIC>;
						clocks = <&rcc CK_ICN_NIC>;
						domain-name = "ck_icn_nic";
						flags = <SCMI_CLOCK_DEFAULT_ENABLED>;
					};

					clock@7 {
						reg = <CK_SCMI_FLEXGEN_07>;
						clocks = <&rcc CK_FLEXGEN_07>;
						domain-name = "ck_flexgen_07";
						flags = <SCMI_CLOCK_DEFAULT_ENABLED>;
					};

					clock@8 {
						reg = <CK_SCMI_FLEXGEN_08>;
						clocks = <&rcc CK_FLEXGEN_08>;
						domain-name = "ck_flexgen_08";
						flags = <SCMI_CLOCK_DEFAULT_ENABLED>;
					};

					clock@9 {
						reg = <CK_SCMI_FLEXGEN_09>;
						clocks = <&rcc CK_FLEXGEN_09>;
						domain-name = "ck_flexgen_09";
						flags = <SCMI_CLOCK_DEFAULT_ENABLED>;
					};

					clock@a {
						reg = <CK_SCMI_FLEXGEN_10>;
						clocks = <&rcc CK_FLEXGEN_10>;
						domain-name = "ck_flexgen_10";
						flags = <(SCMI_CLOCK_DEFAULT_ENABLED |
							  SCMI_CLOCK_ALLOW_SET_RATE)>;
					};

					clock@b {
						reg = <CK_SCMI_FLEXGEN_11>;
						clocks = <&rcc CK_FLEXGEN_11>;
						domain-name = "ck_flexgen_11";
						flags = <(SCMI_CLOCK_DEFAULT_ENABLED |
							  SCMI_CLOCK_ALLOW_SET_RATE)>;
					};

					clock@c {
						reg = <CK_SCMI_FLEXGEN_12>;
						clocks = <&rcc CK_FLEXGEN_12>;
						domain-name = "ck_flexgen_12";
						flags = <SCMI_CLOCK_DEFAULT_ENABLED>;
					};

					clock@d {
						reg = <CK_SCMI_FLEXGEN_13>;
						clocks = <&rcc CK_FLEXGEN_13>;
						domain-name = "ck_flexgen_13";
						flags = <SCMI_CLOCK_DEFAULT_ENABLED>;
					};

					clock@e {
						reg = <CK_SCMI_FLEXGEN_14>;
						clocks = <&rcc CK_FLEXGEN_14>;
						domain-name = "ck_flexgen_14";
						flags = <SCMI_CLOCK_DEFAULT_ENABLED>;
					};

					clock@f {
						reg = <CK_SCMI_FLEXGEN_15>;
						clocks = <&rcc CK_FLEXGEN_15>;
						domain-name = "ck_flexgen_15";
						flags = <SCMI_CLOCK_DEFAULT_ENABLED>;
					};

					clock@10 {
						reg = <CK_SCMI_FLEXGEN_16>;
						clocks = <&rcc CK_FLEXGEN_16>;
						domain-name = "ck_flexgen_16";
						flags = <(SCMI_CLOCK_DEFAULT_ENABLED |
							  SCMI_CLOCK_ALLOW_SET_RATE)>;
					};

					clock@11 {
						reg = <CK_SCMI_FLEXGEN_17>;
						clocks = <&rcc CK_FLEXGEN_17>;
						domain-name = "ck_flexgen_17";
						flags = <SCMI_CLOCK_DEFAULT_ENABLED>;
					};

					clock@12 {
						reg = <CK_SCMI_FLEXGEN_18>;
						clocks = <&rcc CK_FLEXGEN_18>;
						domain-name = "ck_flexgen_18";
						flags = <SCMI_CLOCK_DEFAULT_ENABLED>;
					};

					clock@13 {
						reg = <CK_SCMI_FLEXGEN_19>;
						clocks = <&rcc CK_FLEXGEN_19>;
						domain-name = "ck_flexgen_19";
						flags = <SCMI_CLOCK_DEFAULT_ENABLED>;
					};

					clock@14 {
						reg = <CK_SCMI_FLEXGEN_20>;
						clocks = <&rcc CK_FLEXGEN_20>;
						domain-name = "ck_flexgen_20";
						flags = <SCMI_CLOCK_DEFAULT_ENABLED>;
					};

					clock@15 {
						reg = <CK_SCMI_FLEXGEN_21>;
						clocks = <&rcc CK_FLEXGEN_21>;
						domain-name = "ck_flexgen_21";
						flags = <SCMI_CLOCK_DEFAULT_ENABLED>;
					};

					clock@16 {
						reg = <CK_SCMI_FLEXGEN_22>;
						clocks = <&rcc CK_FLEXGEN_22>;
						domain-name = "ck_flexgen_22";
						flags = <(SCMI_CLOCK_DEFAULT_ENABLED |
							  SCMI_CLOCK_ALLOW_SET_RATE)>;
					};

					clock@17 {
						reg = <CK_SCMI_FLEXGEN_23>;
						clocks = <&rcc CK_FLEXGEN_23>;
						domain-name = "ck_flexgen_23";
						flags = <(SCMI_CLOCK_DEFAULT_ENABLED |
							  SCMI_CLOCK_ALLOW_SET_RATE)>;
					};

					clock@18 {
						reg = <CK_SCMI_FLEXGEN_24>;
						clocks = <&rcc CK_FLEXGEN_24>;
						domain-name = "ck_flexgen_24";
						flags = <(SCMI_CLOCK_DEFAULT_ENABLED |
							  SCMI_CLOCK_ALLOW_SET_RATE)>;
					};

					clock@19 {
						reg = <CK_SCMI_FLEXGEN_25>;
						clocks = <&rcc CK_FLEXGEN_25>;
						domain-name = "ck_flexgen_25";
						flags = <(SCMI_CLOCK_DEFAULT_ENABLED |
							  SCMI_CLOCK_ALLOW_SET_RATE)>;
					};

					clock@1a {
						reg = <CK_SCMI_FLEXGEN_26>;
						clocks = <&rcc CK_FLEXGEN_26>;
						domain-name = "ck_flexgen_26";
						flags = <SCMI_CLOCK_DEFAULT_ENABLED>;
					};

					clock@1b {
						reg = <CK_SCMI_FLEXGEN_27>;
						clocks = <&rcc CK_FLEXGEN_27>;
						domain-name = "ck_flexgen_27";
						flags = <(SCMI_CLOCK_DEFAULT_ENABLED |
							  SCMI_CLOCK_ALLOW_SET_RATE)>;
					};

					clock@1c {
						reg = <CK_SCMI_FLEXGEN_28>;
						clocks = <&rcc CK_FLEXGEN_28>;
						domain-name = "ck_flexgen_28";
						flags = <SCMI_CLOCK_DEFAULT_ENABLED>;
					};

					clock@1d {
						reg = <CK_SCMI_FLEXGEN_29>;
						clocks = <&rcc CK_FLEXGEN_29>;
						domain-name = "ck_flexgen_29";
						flags = <SCMI_CLOCK_DEFAULT_ENABLED>;
					};

					clock@1e {
						reg = <CK_SCMI_FLEXGEN_30>;
						clocks = <&rcc CK_FLEXGEN_30>;
						domain-name = "ck_flexgen_30";
						flags = <SCMI_CLOCK_DEFAULT_ENABLED>;
					};

					clock@1f {
						reg = <CK_SCMI_FLEXGEN_31>;
						clocks = <&rcc CK_FLEXGEN_31>;
						domain-name = "ck_flexgen_31";
						flags = <SCMI_CLOCK_DEFAULT_ENABLED>;
					};

					clock@20 {
						reg = <CK_SCMI_FLEXGEN_32>;
						clocks = <&rcc CK_FLEXGEN_32>;
						domain-name = "ck_flexgen_32";
						flags = <SCMI_CLOCK_DEFAULT_ENABLED>;
					};

					clock@21 {
						reg = <CK_SCMI_FLEXGEN_33>;
						clocks = <&rcc CK_FLEXGEN_33>;
						domain-name = "ck_flexgen_33";
						flags = <SCMI_CLOCK_DEFAULT_ENABLED>;
					};

					clock@22 {
						reg = <CK_SCMI_FLEXGEN_34>;
						clocks = <&rcc CK_FLEXGEN_34>;
						domain-name = "ck_flexgen_34";
						flags = <SCMI_CLOCK_DEFAULT_ENABLED>;
					};

					clock@23 {
						reg = <CK_SCMI_FLEXGEN_35>;
						clocks = <&rcc CK_FLEXGEN_35>;
						domain-name = "ck_flexgen_35";
						flags = <SCMI_CLOCK_DEFAULT_ENABLED>;
					};

					clock@24 {
						reg = <CK_SCMI_FLEXGEN_36>;
						clocks = <&rcc CK_FLEXGEN_36>;
						domain-name = "ck_flexgen_36";
						flags = <SCMI_CLOCK_DEFAULT_ENABLED>;
					};

					clock@25 {
						reg = <CK_SCMI_FLEXGEN_37>;
						clocks = <&rcc CK_FLEXGEN_37>;
						domain-name = "ck_flexgen_37";
						flags = <SCMI_CLOCK_DEFAULT_ENABLED>;
					};

					clock@26 {
						reg = <CK_SCMI_FLEXGEN_38>;
						clocks = <&rcc CK_FLEXGEN_38>;
						domain-name = "ck_flexgen_38";
						flags = <SCMI_CLOCK_DEFAULT_ENABLED>;
					};

					clock@27 {
						reg = <CK_SCMI_FLEXGEN_39>;
						clocks = <&rcc CK_FLEXGEN_39>;
						domain-name = "ck_flexgen_39";
						flags = <SCMI_CLOCK_DEFAULT_ENABLED>;
					};

					clock@28 {
						reg = <CK_SCMI_FLEXGEN_40>;
						clocks = <&rcc CK_FLEXGEN_40>;
						domain-name = "ck_flexgen_40";
						flags = <SCMI_CLOCK_DEFAULT_ENABLED>;
					};

					clock@29 {
						reg = <CK_SCMI_FLEXGEN_41>;
						clocks = <&rcc CK_FLEXGEN_41>;
						domain-name = "ck_flexgen_41";
						flags = <SCMI_CLOCK_DEFAULT_ENABLED>;
					};

					clock@2a {
						reg = <CK_SCMI_FLEXGEN_42>;
						clocks = <&rcc CK_FLEXGEN_42>;
						domain-name = "ck_flexgen_42";
						flags = <SCMI_CLOCK_DEFAULT_ENABLED>;
					};

					clock@2b {
						reg = <CK_SCMI_FLEXGEN_43>;
						clocks = <&rcc CK_FLEXGEN_43>;
						domain-name = "ck_flexgen_43";
						flags = <SCMI_CLOCK_DEFAULT_ENABLED>;
					};

					clock@2c {
						reg = <CK_SCMI_FLEXGEN_44>;
						clocks = <&rcc CK_FLEXGEN_44>;
						domain-name = "ck_flexgen_44";
						flags = <SCMI_CLOCK_DEFAULT_ENABLED>;
					};

					clock@2d {
						reg = <CK_SCMI_FLEXGEN_45>;
						clocks = <&rcc CK_FLEXGEN_45>;
						domain-name = "ck_flexgen_45";
						flags = <SCMI_CLOCK_DEFAULT_ENABLED>;
					};

					clock@2e {
						reg = <CK_SCMI_FLEXGEN_46>;
						clocks = <&rcc CK_FLEXGEN_46>;
						domain-name = "ck_flexgen_46";
						flags = <SCMI_CLOCK_DEFAULT_ENABLED>;
					};

					clock@2f {
						reg = <CK_SCMI_FLEXGEN_47>;
						clocks = <&rcc CK_FLEXGEN_47>;
						domain-name = "ck_flexgen_47";
						flags = <SCMI_CLOCK_DEFAULT_ENABLED>;
					};

					clock@30 {
						reg = <CK_SCMI_FLEXGEN_48>;
						clocks = <&rcc CK_FLEXGEN_48>;
						domain-name = "ck_flexgen_48";
						flags = <SCMI_CLOCK_DEFAULT_ENABLED>;
					};

					clock@31 {
						reg = <CK_SCMI_FLEXGEN_49>;
						clocks = <&rcc CK_FLEXGEN_49>;
						domain-name = "ck_flexgen_49";
						flags = <SCMI_CLOCK_DEFAULT_ENABLED>;
					};

					clock@32 {
						reg = <CK_SCMI_FLEXGEN_50>;
						clocks = <&rcc CK_FLEXGEN_50>;
						domain-name = "ck_flexgen_50";
						flags = <SCMI_CLOCK_DEFAULT_ENABLED>;
					};

					clock@33 {
						reg = <CK_SCMI_FLEXGEN_51>;
						clocks = <&rcc CK_FLEXGEN_51>;
						domain-name = "ck_flexgen_51";
						flags = <SCMI_CLOCK_DEFAULT_ENABLED>;
					};

					clock@34 {
						reg = <CK_SCMI_FLEXGEN_52>;
						clocks = <&rcc CK_FLEXGEN_52>;
						domain-name = "ck_flexgen_52";
						flags = <SCMI_CLOCK_DEFAULT_ENABLED>;
					};

					clock@35 {
						reg = <CK_SCMI_FLEXGEN_53>;
						clocks = <&rcc CK_FLEXGEN_53>;
						domain-name = "ck_flexgen_53";
						flags = <SCMI_CLOCK_DEFAULT_ENABLED>;
					};

					clock@36 {
						reg = <CK_SCMI_FLEXGEN_54>;
						clocks = <&rcc CK_FLEXGEN_54>;
						domain-name = "ck_flexgen_54";
						flags = <SCMI_CLOCK_DEFAULT_ENABLED>;
					};

					clock@37 {
						reg = <CK_SCMI_FLEXGEN_55>;
						clocks = <&rcc CK_FLEXGEN_55>;
						domain-name = "ck_flexgen_55";
						flags = <SCMI_CLOCK_DEFAULT_ENABLED>;
					};

					clock@38 {
						reg = <CK_SCMI_FLEXGEN_56>;
						clocks = <&rcc CK_FLEXGEN_56>;
						domain-name = "ck_flexgen_56";
						flags = <SCMI_CLOCK_DEFAULT_ENABLED>;
					};

					clock@39 {
						reg = <CK_SCMI_FLEXGEN_57>;
						clocks = <&rcc CK_FLEXGEN_57>;
						domain-name = "ck_flexgen_57";
						flags = <SCMI_CLOCK_DEFAULT_ENABLED>;
					};

					clock@3a {
						reg = <CK_SCMI_FLEXGEN_58>;
						clocks = <&rcc CK_FLEXGEN_58>;
						domain-name = "ck_flexgen_58";
						flags = <SCMI_CLOCK_DEFAULT_ENABLED>;
					};

					clock@3b {
						reg = <CK_SCMI_FLEXGEN_59>;
						clocks = <&rcc CK_FLEXGEN_59>;
						domain-name = "ck_flexgen_59";
						flags = <SCMI_CLOCK_DEFAULT_ENABLED>;
					};

					clock@3c {
						reg = <CK_SCMI_FLEXGEN_60>;
						clocks = <&rcc CK_FLEXGEN_60>;
						domain-name = "ck_flexgen_60";
						flags = <SCMI_CLOCK_DEFAULT_ENABLED>;
					};

					clock@3d {
						reg = <CK_SCMI_FLEXGEN_61>;
						clocks = <&rcc CK_FLEXGEN_61>;
						domain-name = "ck_flexgen_61";
						flags = <SCMI_CLOCK_DEFAULT_ENABLED>;
					};

					clock@3e {
						reg = <CK_SCMI_FLEXGEN_62>;
						clocks = <&rcc CK_FLEXGEN_62>;
						domain-name = "ck_flexgen_62";
						flags = <SCMI_CLOCK_DEFAULT_ENABLED>;
					};

					clock@3f {
						reg = <CK_SCMI_FLEXGEN_63>;
						clocks = <&rcc CK_FLEXGEN_63>;
						domain-name = "ck_flexgen_63";
						flags = <SCMI_CLOCK_DEFAULT_ENABLED>;
					};

					clock@40 {
						reg = <CK_SCMI_ICN_LS_MCU>;
						clocks = <&rcc CK_ICN_LS_MCU>;
						domain-name = "ck_icn_ls_mcu";
						flags = <SCMI_CLOCK_DEFAULT_ENABLED>;
					};

					clock@41 {
						reg = <CK_SCMI_HSE>;
						clocks = <&rcc HSE_CK>;
						domain-name = "hse_ck";
						flags = <SCMI_CLOCK_DEFAULT_ENABLED>;
					};

					clock@42 {
						reg = <CK_SCMI_LSE>;
						clocks = <&rcc LSE_CK>;
						domain-name = "lse_ck";
						flags = <SCMI_CLOCK_DEFAULT_ENABLED>;
					};

					clock@43 {
						reg = <CK_SCMI_HSI>;
						clocks = <&rcc HSI_CK>;
						domain-name = "hsi_ck";
						flags = <SCMI_CLOCK_DEFAULT_ENABLED>;
					};

					clock@44 {
						reg = <CK_SCMI_LSI>;
						clocks = <&rcc LSI_CK>;
						domain-name = "lsi_ck";
						flags = <SCMI_CLOCK_DEFAULT_ENABLED>;
					};

					clock@45 {
						reg = <CK_SCMI_MSI>;
						clocks = <&rcc MSI_CK>;
						domain-name = "msi_ck";
						flags = <SCMI_CLOCK_DEFAULT_ENABLED>;
					};

					clock@46 {
						reg = <CK_SCMI_HSE_DIV2>;
						clocks = <&rcc HSE_DIV2_CK>;
						domain-name = "hse_div2_ck";
					};

					clock@47 {
						reg = <CK_SCMI_CPU1>;
						clocks = <&rcc CK_CPU1>;
						domain-name = "ck_cpu1";
						flags = <SCMI_CLOCK_DEFAULT_ENABLED>;
					};

					clock@48 {
						reg = <CK_SCMI_SYSCPU1>;
						clocks = <&rcc CK_BUS_SYSCPU1>;
						domain-name = "ck_bus_syscpu1";
						flags = <SCMI_CLOCK_DEFAULT_ENABLED>;
					};

					clock@49 {
						reg = <CK_SCMI_PLL2>;
						clocks = <&rcc PLL2_CK>;
						domain-name = "ck_pll2";
						flags = <SCMI_CLOCK_DEFAULT_ENABLED>;
					};

					clock@4a {
						reg = <CK_SCMI_RTC>;
						clocks = <&rcc CK_BUS_RTC>;
						domain-name = "ck_bus_rtc";
						flags = <SCMI_CLOCK_DEFAULT_ENABLED>;
					};

					clock@4b {
						reg = <CK_SCMI_RTCCK>;
						clocks = <&rcc RTC_CK>;
						domain-name = "rtc_ck";
						flags = <SCMI_CLOCK_DEFAULT_ENABLED>;
					};

					clock@4c {
						reg = <CK_SCMI_ICN_APB1>;
						clocks = <&rcc CK_ICN_APB1>;
						domain-name = "ck_icn_apb1";
						flags = <SCMI_CLOCK_DEFAULT_ENABLED>;
					};

					clock@4d {
						reg = <CK_SCMI_ICN_APB2>;
						clocks = <&rcc CK_ICN_APB2>;
						domain-name = "ck_icn_apb2";
						flags = <SCMI_CLOCK_DEFAULT_ENABLED>;
					};

					clock@4e {
						reg = <CK_SCMI_ICN_APB3>;
						clocks = <&rcc CK_ICN_APB3>;
						domain-name = "ck_icn_apb3";
						flags = <SCMI_CLOCK_DEFAULT_ENABLED>;
					};

					clock@4f {
						reg = <CK_SCMI_ICN_APB4>;
						clocks = <&rcc CK_ICN_APB4>;
						domain-name = "ck_icn_apb4";
						flags = <SCMI_CLOCK_DEFAULT_ENABLED>;
					};

					clock@50 {
						reg = <CK_SCMI_ICN_APB5>;
						clocks = <&rcc CK_ICN_APB5>;
						domain-name = "ck_icn_apb5";
						flags = <SCMI_CLOCK_DEFAULT_ENABLED>;
					};

					clock@51 {
						reg = <CK_SCMI_ICN_APBDBG>;
						clocks = <&rcc CK_ICN_APBDBG>;
						domain-name = "ck_icn_apbdbg";
						flags = <SCMI_CLOCK_DEFAULT_ENABLED>;
					};

					clock@52 {
						reg = <CK_SCMI_TIMG1>;
						clocks = <&rcc TIMG1_CK>;
						domain-name = "timg1_ck";
						flags = <SCMI_CLOCK_DEFAULT_ENABLED>;
					};

					clock@53 {
						reg = <CK_SCMI_TIMG2>;
						clocks = <&rcc TIMG2_CK>;
						domain-name = "timg2_ck";
						flags = <SCMI_CLOCK_DEFAULT_ENABLED>;
					};

					clock@54 {
						reg = <CK_SCMI_BKPSRAM>;
						clocks = <&rcc CK_BUS_BKPSRAM>;
						domain-name = "ck_bus_bkpsram";
						flags = <SCMI_CLOCK_DEFAULT_ENABLED>;
					};

					clock@55 {
						reg = <CK_SCMI_BSEC>;
						clocks = <&rcc CK_BUS_BSEC>;
						domain-name = "ck_bus_bsec";
						flags = <SCMI_CLOCK_DEFAULT_ENABLED>;
					};

					clock@56 {
						reg = <CK_SCMI_BUS_ETR>;
						clocks = <&rcc CK_BUS_ETR>;
						domain-name = "ck_icn_p_etr";
						flags = <SCMI_CLOCK_DEFAULT_ENABLED>;
					};

					clock@57 {
						reg = <CK_SCMI_FMC>;
						clocks = <&rcc CK_KER_FMC>;
						domain-name = "ck_ker_fmc";
						flags = <SCMI_CLOCK_DEFAULT_ENABLED>;
					};

					clock@58 {
						reg = <CK_SCMI_GPIOA>;
						clocks = <&rcc CK_BUS_GPIOA>;
						domain-name = "ck_bus_gpioa";
						flags = <SCMI_CLOCK_DEFAULT_ENABLED>;
					};

					clock@59 {
						reg = <CK_SCMI_GPIOB>;
						clocks = <&rcc CK_BUS_GPIOB>;
						domain-name = "ck_bus_gpiob";
						flags = <SCMI_CLOCK_DEFAULT_ENABLED>;
					};

					clock@5a {
						reg = <CK_SCMI_GPIOC>;
						clocks = <&rcc CK_BUS_GPIOC>;
						domain-name = "ck_bus_gpioc";
						flags = <SCMI_CLOCK_DEFAULT_ENABLED>;
					};

					clock@5b {
						reg = <CK_SCMI_GPIOD>;
						clocks = <&rcc CK_BUS_GPIOD>;
						domain-name = "ck_bus_gpiod";
						flags = <SCMI_CLOCK_DEFAULT_ENABLED>;
					};

					clock@5c {
						reg = <CK_SCMI_GPIOE>;
						clocks = <&rcc CK_BUS_GPIOE>;
						domain-name = "ck_bus_gpioe";
						flags = <SCMI_CLOCK_DEFAULT_ENABLED>;
					};

					clock@5d {
						reg = <CK_SCMI_GPIOF>;
						clocks = <&rcc CK_BUS_GPIOF>;
						domain-name = "ck_bus_gpiof";
						flags = <SCMI_CLOCK_DEFAULT_ENABLED>;
					};

					clock@5e {
						reg = <CK_SCMI_GPIOG>;
						clocks = <&rcc CK_BUS_GPIOG>;
						domain-name = "ck_bus_gpiog";
						flags = <SCMI_CLOCK_DEFAULT_ENABLED>;
					};

					clock@5f {
						reg = <CK_SCMI_GPIOH>;
						clocks = <&rcc CK_BUS_GPIOH>;
						domain-name = "ck_bus_gpioh";
						flags = <SCMI_CLOCK_DEFAULT_ENABLED>;
					};

					clock@60 {
						reg = <CK_SCMI_GPIOI>;
						clocks = <&rcc CK_BUS_GPIOI>;
						domain-name = "ck_bus_gpioi";
						flags = <SCMI_CLOCK_DEFAULT_ENABLED>;
					};

					clock@61 {
						reg = <CK_SCMI_GPIOZ>;
						clocks = <&rcc CK_BUS_GPIOZ>;
						domain-name = "ck_bus_gpioz";
						flags = <SCMI_CLOCK_DEFAULT_ENABLED>;
					};

					clock@62 {
						reg = <CK_SCMI_HPDMA1>;
						clocks = <&rcc CK_BUS_HPDMA1>;
						domain-name = "ck_bus_hpdma1";
						flags = <SCMI_CLOCK_DEFAULT_ENABLED>;
					};

					clock@63 {
						reg = <CK_SCMI_HPDMA2>;
						clocks = <&rcc CK_BUS_HPDMA2>;
						domain-name = "ck_bus_hpdma2";
						flags = <SCMI_CLOCK_DEFAULT_ENABLED>;
					};

					clock@64 {
						reg = <CK_SCMI_HPDMA3>;
						clocks = <&rcc CK_BUS_HPDMA3>;
						domain-name = "ck_bus_hpdma3";
						flags = <SCMI_CLOCK_DEFAULT_ENABLED>;
					};

					clock@65 {
						reg = <CK_SCMI_IPCC1>;
						clocks = <&rcc CK_BUS_IPCC1>;
						domain-name = "ck_bus_ipcc1";
						flags = <SCMI_CLOCK_DEFAULT_ENABLED>;
					};

					clock@66 {
						reg = <CK_SCMI_RETRAM>;
						clocks = <&rcc CK_BUS_RETRAM>;
						domain-name = "ck_bus_retram";
						flags = <SCMI_CLOCK_DEFAULT_ENABLED>;
					};

					clock@67 {
						reg = <CK_SCMI_SRAM1>;
						clocks = <&rcc CK_BUS_SRAM1>;
						domain-name = "ck_bus_sram1";
						flags = <SCMI_CLOCK_DEFAULT_ENABLED>;
					};

					clock@68 {
						reg = <CK_SCMI_SYSRAM>;
						clocks = <&rcc CK_BUS_SYSRAM>;
						domain-name = "ck_icn_s_sysram";
						flags = <SCMI_CLOCK_DEFAULT_ENABLED>;
					};

					clock@69 {
						reg = <CK_SCMI_OSPI1>;
						clocks = <&rcc CK_KER_OSPI1>;
						domain-name = "ck_ker_ospi1";
						flags = <SCMI_CLOCK_DEFAULT_ENABLED>;
					};

					clock@6a {
						reg = <CK_SCMI_TPIU>;
						clocks = <&rcc CK_KER_TPIU>;
						domain-name = "ck_ker_tpiu";
						flags = <SCMI_CLOCK_DEFAULT_ENABLED>;
					};

					clock@6b {
						reg = <CK_SCMI_SYSDBG>;
						clocks = <&rcc CK_SYSDBG>;
						domain-name = "ck_sys_dbg";
						flags = <SCMI_CLOCK_DEFAULT_ENABLED>;
					};

					clock@6c {
						reg = <CK_SCMI_SYSATB>;
						clocks = <&rcc CK_BUS_SYSATB>;
						domain-name = "ck_sys_atb";
						flags = <SCMI_CLOCK_DEFAULT_ENABLED>;
					};

					clock@6d {
						reg = <CK_SCMI_TSDBG>;
						clocks = <&rcc CK_KER_TSDBG>;
						domain-name = "ck_ker_tsdbg";
						flags = <SCMI_CLOCK_DEFAULT_ENABLED>;
					};

					clock@6e {
						reg = <CK_SCMI_BUS_STM>;
						clocks = <&rcc CK_BUS_STM>;
						domain-name = "ck_icn_p_stm";
						flags = <SCMI_CLOCK_DEFAULT_ENABLED>;
					};

					clock@6f {
						reg = <CK_SCMI_KER_STM>;
						clocks = <&rcc CK_KER_STM>;
						domain-name = "ck_icn_s_stm";
						flags = <SCMI_CLOCK_DEFAULT_ENABLED>;
					};

					clock@70 {
						reg = <CK_SCMI_KER_ETR>;
						clocks = <&rcc CK_KER_ETR>;
						domain-name = "ck_icn_m_etr";
						flags = <SCMI_CLOCK_DEFAULT_ENABLED>;
					};

					clock@71 {
						reg = <CK_SCMI_HSI_KER_CK>;
						domain-name = "hsi_ker_ck";
						clocks = <&rcc HSI_KER_CK>;
						flags = <SCMI_CLOCK_DEFAULT_ENABLED>;
					};

					clock@72 {
						reg = <CK_SCMI_HSE_KER_CK>;
						domain-name = "hse_ker_ck";
						clocks = <&rcc HSE_KER_CK>;
						flags = <SCMI_CLOCK_DEFAULT_ENABLED>;
					};

					clock@73 {
						reg = <CK_SCMI_MSI_KER_CK>;
						domain-name = "msi_ker_ck";
						clocks = <&rcc MSI_KER_CK>;
						flags = <SCMI_CLOCK_DEFAULT_ENABLED>;
					};
				};
			};

			scmi_reset_m33: protocol@16 {
				reg = <0x16>;

				resets {
					#address-cells = <1>;
					#size-cells = <0>;
					#reset-cells = <1>;

					reset@0 {
						reg = <RST_SCMI_C1_R>;
						domain-name = "c1";
						resets = <&rcc C1_R>;
					};

					reset@1 {
						reg = <RST_SCMI_C2_R>;
						domain-name = "c2";
						resets = <&m33_rproc 0>;
					};

					reset@2 {
						reg = <RST_SCMI_C1_HOLDBOOT_R>;
						domain-name = "c1_holdboot";
						resets = <&rcc C1_HOLDBOOT_R>;
					};

					reset@3 {
						reg = <RST_SCMI_C2_HOLDBOOT_R>;
						domain-name = "c2_holdboot";
						resets = <&m33_rproc 1>;
					};

					reset@4 {
						reg = <RST_SCMI_FMC>;
						domain-name = "fmc";
						resets = <&rcc FMC_R>;
					};

					reset@5 {
						reg = <RST_SCMI_OSPI1>;
						domain-name = "ospi1";
						resets = <&rcc OSPI1_R>;
					};

					reset@6 {
						reg = <RST_SCMI_OSPI1DLL>;
						domain-name = "ospi1_ddl";
						resets = <&rcc OSPI1DLL_R>;
					};
				};
			};

			scmi_regulator_m33: protocol@17 {
				reg = <0x17>;

				regulators {
					#address-cells = <1>;
					#size-cells = <0>;

					voltd-vddio1 {
						reg = <VOLTD_SCMI_VDDIO1>;
						voltd-supply = <&vddio1>;
					};

					voltd-vddio2 {
						reg = <VOLTD_SCMI_VDDIO2>;
						voltd-supply = <&vddio2>;
					};

					voltd-vddio3 {
						reg = <VOLTD_SCMI_VDDIO3>;
						voltd-supply = <&vddio3>;
					};

					voltd-vdda18adc {
						reg = <VOLTD_SCMI_ADC>;
						voltd-supply = <&vdda18adc>;
					};
				};
			};
		};
	};

	soc@0 {
		compatible = "simple-bus";
		#address-cells = <1>;
		#size-cells = <1>;
		interrupt-parent = <&intc>;
		ranges = <0x0 0x0 0x0 0x80000000>;

		hpdma1: dma-controller@40400000 {
			compatible = "st,stm32-dma3";
			reg = <0x40400000 0x1000>;
			clocks = <&rcc CK_BUS_HPDMA1>;
			resets = <&rcc HPDMA1_R>;
			#dma-cells = <4>;
			st,syscfg-arcr = <&syscfg 0x2050 0x1>;
		};

		hpdma2: dma-controller@40410000 {
			compatible = "st,stm32-dma3";
			reg = <0x40410000 0x1000>;
			clocks = <&rcc CK_BUS_HPDMA2>;
			resets = <&rcc HPDMA2_R>;
			#dma-cells = <4>;
			st,syscfg-arcr = <&syscfg 0x2050 0x2>;
		};

		hpdma3: dma-controller@40420000 {
			compatible = "st,stm32-dma3";
			reg = <0x40420000 0x1000>;
			clocks = <&rcc CK_BUS_HPDMA3>;
			resets = <&rcc HPDMA3_R>;
			#dma-cells = <4>;
			st,syscfg-arcr = <&syscfg 0x2050 0x4>;
		};

		ipcc1: mailbox@40490000 {
			compatible = "st,stm32mp25-ipcc";
			reg = <0x40490000 0x400>;
			interrupts = <GIC_SPI 154 IRQ_TYPE_LEVEL_HIGH>;
			interrupt-names = "rx";
			clocks = <&rcc CK_BUS_IPCC1>;
		};

		rifsc: bus@42080000 {
			compatible = "st,stm32mp25-rifsc", "simple-bus";
			reg = <0x42080000 0x1000>;
			#address-cells = <1>;
			#size-cells = <1>;
			#access-controller-cells = <1>;

			lptimer1: timer@40090000 {
				compatible = "st,stm32mp21-lptimer";
				reg = <0x40090000 0x400>;
				interrupts = <GIC_SPI 149 IRQ_TYPE_LEVEL_HIGH>;
				clocks = <&rcc CK_KER_LPTIM1>;
				clock-names = "mux";
				#address-cells = <1>;
				#size-cells = <0>;
				access-controllers = <&rifsc STM32MP21_RIFSC_LPTIM1_ID>;
				status = "disabled";

				counter {
					compatible = "st,stm32mp21-lptimer-counter";
					status = "disabled";
				};

				pwm {
					compatible = "st,stm32mp21-pwm-lp";
					#pwm-cells = <3>;
					status = "disabled";
				};

				timer {
					compatible = "st,stm32mp21-lptimer-timer";
					status = "disabled";
				};

				trigger@0 {
					compatible = "st,stm32mp21-lptimer-trigger";
					reg = <0>;
					status = "disabled";
				};
			};

			lptimer2: timer@400a0000 {
				compatible = "st,stm32mp21-lptimer";
				reg = <0x400a0000 0x400>;
				interrupts = <GIC_SPI 180 IRQ_TYPE_LEVEL_HIGH>;
				clocks = <&rcc CK_KER_LPTIM2>;
				clock-names = "mux";
				#address-cells = <1>;
				#size-cells = <0>;
				status = "disabled";

				counter {
					compatible = "st,stm32mp21-lptimer-counter";
					status = "disabled";
				};

				pwm {
					compatible = "st,stm32mp21-pwm-lp";
					#pwm-cells = <3>;
					status = "disabled";
				};

				timer {
					compatible = "st,stm32mp21-lptimer-timer";
					status = "disabled";
				};

				trigger@1 {
					compatible = "st,stm32mp21-lptimer-trigger";
					reg = <1>;
					status = "disabled";
				};
			};

			usart2: serial@400e0000 {
				compatible = "st,stm32h7-uart";
				reg = <0x400e0000 0x400>;
				interrupts = <GIC_SPI 102 IRQ_TYPE_LEVEL_HIGH>;
				clocks = <&rcc CK_KER_USART2>;
				access-controllers = <&rifsc STM32MP21_RIFSC_USART2_ID>;
				status = "disabled";
			};

			usart3: serial@400f0000 {
				compatible = "st,stm32h7-uart";
				reg = <0x400f0000 0x400>;
				interrupts = <GIC_SPI 103 IRQ_TYPE_LEVEL_HIGH>;
				clocks = <&rcc CK_KER_USART3>;
				access-controllers = <&rifsc STM32MP21_RIFSC_USART3_ID>;
				status = "disabled";
			};

			uart4: serial@40100000 {
				compatible = "st,stm32h7-uart";
				reg = <0x40100000 0x400>;
				interrupts = <GIC_SPI 113 IRQ_TYPE_LEVEL_HIGH>;
				clocks = <&rcc CK_KER_UART4>;
				access-controllers = <&rifsc STM32MP21_RIFSC_UART4_ID>;
				status = "disabled";
			};

			uart5: serial@40110000 {
				compatible = "st,stm32h7-uart";
				reg = <0x40110000 0x400>;
				interrupts = <GIC_SPI 114 IRQ_TYPE_LEVEL_HIGH>;
				clocks = <&rcc CK_KER_UART5>;
				access-controllers = <&rifsc STM32MP21_RIFSC_UART5_ID>;
				status = "disabled";
			};

			i2c1: i2c@40170000 {
				compatible = "st,stm32mp25-i2c";
				reg = <0x40170000 0x400>;
				clocks = <&rcc CK_KER_I2C1>;
				resets = <&rcc I2C1_R>;
				#address-cells = <1>;
				#size-cells = <0>;
				i2c-analog-filter;
				access-controllers = <&rifsc STM32MP21_RIFSC_I2C1_ID>;
				status = "disabled";
			};

			i2c2: i2c@40180000 {
				compatible = "st,stm32mp25-i2c";
				reg = <0x40180000 0x400>;
				clocks = <&rcc CK_KER_I2C1>;
				resets = <&rcc I2C1_R>;
				#address-cells = <1>;
				#size-cells = <0>;
				i2c-analog-filter;
				access-controllers = <&rifsc STM32MP21_RIFSC_I2C2_ID>;
				status = "disabled";
			};

			usart6: serial@40220000 {
				compatible = "st,stm32h7-uart";
				reg = <0x40220000 0x400>;
				interrupts = <GIC_SPI 123 IRQ_TYPE_LEVEL_HIGH>;
				clocks = <&rcc CK_KER_USART6>;
				access-controllers = <&rifsc STM32MP21_RIFSC_USART6_ID>;
				status = "disabled";
			};

			usart1: serial@40330000 {
				compatible = "st,stm32h7-uart";
				reg = <0x40330000 0x400>;
				interrupts = <GIC_SPI 101 IRQ_TYPE_LEVEL_HIGH>;
				clocks = <&rcc CK_KER_USART1>;
				access-controllers = <&rifsc STM32MP21_RIFSC_USART1_ID>;
				status = "disabled";
			};

			uart7: serial@40370000 {
				compatible = "st,stm32h7-uart";
				reg = <0x40370000 0x400>;
				interrupts = <GIC_SPI 135 IRQ_TYPE_LEVEL_HIGH>;
				clocks = <&rcc CK_KER_UART7>;
				access-controllers = <&rifsc STM32MP21_RIFSC_UART7_ID>;
				status = "disabled";
			};

			adc_1: adc@404e0000 {
				compatible = "st,stm32mp21-adc-core";
				reg = <0x404e0000 0x400>;
				interrupts = <GIC_SPI 81 IRQ_TYPE_LEVEL_HIGH>;
				clocks = <&rcc CK_KER_ADC1>;
				clock-names = "adc";
				interrupt-controller;
				#interrupt-cells = <1>;
				#address-cells = <1>;
				#size-cells = <0>;
				access-controllers = <&rifsc STM32MP21_RIFSC_ADC1_ID>;
				status = "disabled";

				adc1: adc@0 {
					compatible = "st,stm32mp21-adc";
					#io-channel-cells = <1>;
					#address-cells = <1>;
					#size-cells = <0>;
					reg = <0x0>;
					interrupt-parent = <&adc_1>;
					interrupts = <0>;
					status = "disabled";

					channel@14 {
						reg = <14>;
						label = "vrefint";
					};
				};
			};

			adc_2: adc@404f0000 {
				compatible = "st,stm32mp21-adc-core";
				reg = <0x404f0000 0x400>;
				interrupts = <GIC_SPI 82 IRQ_TYPE_LEVEL_HIGH>;
				clocks = <&rcc CK_KER_ADC2>;
				clock-names = "adc";
				interrupt-controller;
				#interrupt-cells = <1>;
				#address-cells = <1>;
				#size-cells = <0>;
				access-controllers = <&rifsc STM32MP21_RIFSC_ADC2_ID>;
				status = "disabled";

				adc2: adc@0 {
					compatible = "st,stm32mp21-adc";
					#io-channel-cells = <1>;
					#address-cells = <1>;
					#size-cells = <0>;
					reg = <0x0>;
					interrupt-parent = <&adc_2>;
					interrupts = <0>;
					status = "disabled";

					channel@14 {
						reg = <14>;
						label = "vrefint";
					};
					channel@15 {
						reg = <15>;
						label = "vddcore";
					};
					channel@17 {
						reg = <17>;
						label = "vddcpu";
					};
				};
			};

			hash2: hash@42010000  {
				compatible = "st,stm32mp13-hash";
				reg = <0x42010000  0x400>;
				interrupts = <GIC_SPI 178 IRQ_TYPE_LEVEL_HIGH>;
				clocks = <&rcc CK_BUS_HASH2>;
				resets = <&rcc HASH2_R>;
				access-controllers = <&rifsc STM32MP21_RIFSC_HASH2_ID>;
				status = "disabled";
			};

			rng2: rng@42020000 {
				compatible = "st,stm32mp21-rng";
				reg = <0x42020000 0x400>;
				clocks = <&clk_rcbsec>, <&rcc CK_BUS_RNG2>;
				clock-names = "rng_clk", "rng_hclk";
				access-controllers = <&rifsc STM32MP21_RIFSC_RNG2_ID>;
				resets = <&rcc RNG2_R>;
			};

			iwdg1: watchdog@44010000 {
				compatible = "st,stm32mp1-iwdg";
				reg = <0x44010000 0x400>;
				interrupts = <GIC_SPI 2 IRQ_TYPE_LEVEL_HIGH>;
				clocks = <&rcc CK_BUS_IWDG1>, <&rcc LSI_CK>;
				clock-names = "pclk", "lsi";
				access-controllers = <&rifsc STM32MP21_RIFSC_IWDG1_ID>;
				status = "disabled";
			};

			iwdg2: watchdog@44020000 {
				compatible = "st,stm32mp1-iwdg";
				reg = <0x44020000 0x400>;
				interrupts = <GIC_SPI 3 IRQ_TYPE_LEVEL_HIGH>;
				clocks = <&rcc CK_BUS_IWDG2>, <&rcc LSI_CK>;
				clock-names = "pclk", "lsi";
				resets = <&rcc IWDG2_SYS_R>;
				access-controllers = <&rifsc STM32MP21_RIFSC_IWDG2_ID>;
				status = "disabled";
			};

			i2c3: i2c@46040000 {
				compatible = "st,stm32mp25-i2c";
				reg = <0x46040000 0x400>;
				clocks = <&rcc CK_KER_I2C3>;
				resets = <&rcc I2C3_R>;
				i2c-analog-filter;
				#address-cells = <1>;
				#size-cells = <0>;
				access-controllers = <&rifsc STM32MP21_RIFSC_I2C3_ID>;
				status = "disabled";
			};

			lptimer3: timer@46050000 {
				compatible = "st,stm32mp21-lptimer";
				reg = <0x46050000 0x400>;
				interrupts = <GIC_SPI 181 IRQ_TYPE_LEVEL_HIGH>;
				clocks = <&rcc CK_KER_LPTIM3>;
				clock-names = "mux";
				#address-cells = <1>;
				#size-cells = <0>;
				status = "disabled";

				counter {
					compatible = "st,stm32mp21-lptimer-counter";
					status = "disabled";
				};

				pwm {
					compatible = "st,stm32mp21-pwm-lp";
					#pwm-cells = <3>;
					status = "disabled";
				};

				timer {
					compatible = "st,stm32mp21-lptimer-timer";
					status = "disabled";
				};

				trigger@2 {
					compatible = "st,stm32mp21-lptimer-trigger";
					reg = <2>;
					status = "disabled";
				};
			};

			lptimer4: timer@46060000 {
				compatible = "st,stm32mp21-lptimer";
				reg = <0x46060000 0x400>;
				interrupts = <GIC_SPI 182 IRQ_TYPE_LEVEL_HIGH>;
				clocks = <&rcc CK_KER_LPTIM4>;
				clock-names = "mux";
				#address-cells = <1>;
				#size-cells = <0>;
				status = "disabled";

				counter {
					compatible = "st,stm32mp21-lptimer-counter";
					status = "disabled";
				};

				pwm {
					compatible = "st,stm32mp21-pwm-lp";
					#pwm-cells = <3>;
					status = "disabled";
				};

				timer {
					compatible = "st,stm32mp21-lptimer-timer";
					status = "disabled";
				};

				trigger@3 {
					compatible = "st,stm32mp21-lptimer-trigger";
					reg = <3>;
					status = "disabled";
				};
			};

			lptimer5: timer@46070000 {
				compatible = "st,stm32mp21-lptimer";
				reg = <0x46070000 0x400>;
				interrupts = <GIC_SPI 183 IRQ_TYPE_LEVEL_HIGH>;
				clocks = <&rcc CK_KER_LPTIM5>;
				clock-names = "mux";
				#address-cells = <1>;
				#size-cells = <0>;
				status = "disabled";

				counter {
					compatible = "st,stm32mp21-lptimer-counter";
					status = "disabled";
				};

				pwm {
					compatible = "st,stm32mp21-pwm-lp";
					#pwm-cells = <3>;
					status = "disabled";
				};

				timer {
					compatible = "st,stm32mp21-lptimer-timer";
					status = "disabled";
				};

				trigger@4 {
					compatible = "st,stm32mp21-lptimer-trigger";
					reg = <4>;
					status = "disabled";
				};
			};
		};

		iac: iac@42090000 {
			compatible = "st,stm32mp25-iac";
			reg = <0x42090000 0x400>;
			interrupts = <GIC_SPI 201 IRQ_TYPE_LEVEL_HIGH>;
		};

		risaf1: risaf@420a0000 {
			compatible = "st,stm32mp25-risaf";
			reg = <0x420a0000 0x1000>;
			clocks = <&rcc CK_BUS_BKPSRAM>;
			st,mem-map = <0x0 0x42000000 0x0 0x2000>;
			#access-controller-cells = <1>;
		};

		risaf2: risaf@420b0000 {
			compatible = "st,stm32mp25-risaf";
			reg = <0x420b0000 0x1000>;
			clocks = <&rcc CK_KER_OSPI1>;
			st,mem-map = <0x0 0x60000000 0x0 0x10000000>;
			status = "disabled";
			#access-controller-cells = <1>;
		};

		risaf4: risaf@420d0000 {
			compatible = "st,stm32mp25-risaf-enc";
			reg = <0x420d0000 0x1000>;
			clocks = <&rcc CK_BUS_RISAF4>;
			st,mem-map = <0x0 0x80000000 0x1 0x00000000>;
			#access-controller-cells = <1>;
		};

		risab1: risab@420f0000 {
			compatible = "st,stm32mp25-risab";
			reg = <0x420f0000 0x1000>;
			clocks = <&rcc CK_ICN_LS_MCU>;
			st,mem-map = <0xa000000 0x20000>;
			#access-controller-cells = <1>;
		};

		risab2: risab@42100000 {
			compatible = "st,stm32mp25-risab";
			reg = <0x42100000 0x1000>;
			clocks = <&rcc CK_ICN_LS_MCU>;
			st,mem-map = <0xa020000 0x20000>;
			#access-controller-cells = <1>;
		};

		risab3: risab@42110000 {
			compatible = "st,stm32mp25-risab";
			reg = <0x42110000 0x1000>;
			clocks = <&rcc CK_ICN_LS_MCU>;
			st,mem-map = <0x0a060000 0x10000>;
			#access-controller-cells = <1>;
		};

		risab5: risab@42130000 {
			compatible = "st,stm32mp25-risab";
			reg = <0x42130000 0x1000>;
			clocks = <&rcc CK_ICN_LS_MCU>;
			st,mem-map = <0x0a040000 0x20000>;
			#access-controller-cells = <1>;
		};

		bsec: efuse@44000000 {
			compatible = "st,stm32mp25-bsec";
			reg = <0x44000000 0x1000>;
			#address-cells = <1>;
			#size-cells = <1>;

			part_number_otp@24 {
				reg = <0x24 0x4>;
			};

			package_otp@1e8 {
				reg = <0x1e8 0x1>;
			};

			hconf1_otp: otp124@1f0 {
				reg = <0x1f0 0x4>;
			};

			pkh_otp: otp152@260 {
				reg = <0x260 0x20>;
			};

			oem_fip_enc_key: otp260@410 {
				reg = <0x410 0x20>;
				st,non-secure-otp-provisioning;
			};

			oem_enc_key_2: otp348@570 {
				reg = <0x570 0x20>;
				st,non-secure-otp-provisioning;
			};

			oem_enc_key_1: otp356@590 {
				reg = <0x590 0x20>;
				st,non-secure-otp-provisioning;
			};
		};

		vrefbuf: vrefbuf@44060000 {
			compatible = "st,stm32mp25-vrefbuf";
			reg = <0x44060000 0x8>;
			regulator-name = "vrefbuf";
			regulator-min-microvolt = <1210000>;
			regulator-max-microvolt = <1500000>;
			clocks = <&rcc CK_BUS_VREF>;
			vdda-supply = <&vdda18adc>;
			status = "disabled";
		};

		serc: serc@44080000 {
			compatible = "st,stm32mp25-serc";
			reg = <0x44080000 0x1000>;
			interrupts = <GIC_SPI 195 IRQ_TYPE_LEVEL_HIGH>;
			clocks = <&rcc CK_BUS_SERC>;
		};

		rcc: clock-controller@44200000 {
			compatible = "st,stm32mp21-rcc", "syscon";
			reg = <0x44200000 0x10000>;
			interrupts = <GIC_SPI 186 IRQ_TYPE_LEVEL_HIGH>;

			#clock-cells = <1>;
			#reset-cells = <1>;
			clocks = <&clk_hse>, <&clk_hsi>, <&clk_lse>,
				 <&clk_lsi>, <&clk_msi>, <&clk_i2sin>;
			clock-names = "clk-hse", "clk-hsi", "clk-lse",
				      "clk-lsi", "clk-msi", "clk-i2sin";

			hsi_calibration: hsi-calibration {
				compatible = "st,hsi-cal";
				st,cal_hsi_dev = <31>;
				st,cal_hsi_ref = <1953>;
				status = "disabled";
			};

			msi_calibration: msi-calibration {
				compatible = "st,msi-cal";
				status = "disabled";
			};
		};

		pwr: pwr@44210000 {
			compatible = "st,stm32mp21-pwr";
			reg = <0x44210000 0x400>;
			wakeup-parent = <&exti1>;
			interrupts = <GIC_SPI 190 IRQ_TYPE_LEVEL_HIGH>;
			wakeup-gpios = <0>, <0>, <0>, <0>, <0>, <0>;
			status = "disabled";

			vdda18adc: vdda18adc {
				compatible = "st,stm32mp21-pwr-regu";
				regulator-name = "vdda18adc";
				status = "disabled";
			};

			vddio1: vddio1 {
				compatible = "st,stm32mp21-pwr-regu";
				regulator-name = "vddio1";
				status = "disabled";
			};

			vddio2: vddio2 {
				compatible = "st,stm32mp21-pwr-regu";
				regulator-name = "vddio2";
				status = "disabled";
			};

			vddio3: vddio3 {
				compatible = "st,stm32mp21-pwr-regu";
				regulator-name = "vddio3";
				status = "disabled";
			};

			vddio: vddio {
				compatible = "st,stm32mp21-pwr-regu";
				regulator-name = "vddio";
				regulator-always-on;
				status = "disabled";
			};
		};

		exti1: interrupt-controller@44220000 {
			compatible = "st,stm32mp1-exti", "syscon";
			interrupt-controller;
			#interrupt-cells = <2>;
			#address-cells = <0>;
			reg = <0x44220000 0x400>;
			status = "disabled";
		};

		syscfg: syscon@44230000 {
			reg = <0x44230000 0x10000>;
			status = "disabled";
		};

		pinctrl: pinctrl@44240000 {
			#address-cells = <1>;
			#size-cells = <1>;
			compatible = "st,stm32mp215-pinctrl";
			ranges = <0 0x44240000 0x80400>;

			gpioa: gpio@44240000 {
				gpio-controller;
				#gpio-cells = <2>;
				interrupt-controller;
				#interrupt-cells = <2>;
				#access-controller-cells = <1>;
				reg = <0x0 0x400>;
				clocks = <&rcc CK_BUS_GPIOA>;
				st,bank-name = "GPIOA";
				status = "disabled";
			};

			gpiob: gpio@44250000 {
				gpio-controller;
				#gpio-cells = <2>;
				interrupt-controller;
				#interrupt-cells = <2>;
				#access-controller-cells = <1>;
				reg = <0x10000 0x400>;
				clocks = <&rcc CK_BUS_GPIOB>;
				st,bank-name = "GPIOB";
				status = "disabled";
			};

			gpioc: gpio@44260000 {
				gpio-controller;
				#gpio-cells = <2>;
				interrupt-controller;
				#interrupt-cells = <2>;
				#access-controller-cells = <1>;
				reg = <0x20000 0x400>;
				clocks = <&rcc CK_BUS_GPIOC>;
				st,bank-name = "GPIOC";
				status = "disabled";
			};

			gpiod: gpio@44270000 {
				gpio-controller;
				#gpio-cells = <2>;
				interrupt-controller;
				#interrupt-cells = <2>;
				#access-controller-cells = <1>;
				reg = <0x30000 0x400>;
				clocks = <&rcc CK_BUS_GPIOD>;
				st,bank-name = "GPIOD";
				status = "disabled";
			};

			gpioe: gpio@44280000 {
				gpio-controller;
				#gpio-cells = <2>;
				interrupt-controller;
				#interrupt-cells = <2>;
				#access-controller-cells = <1>;
				reg = <0x40000 0x400>;
				clocks = <&rcc CK_BUS_GPIOE>;
				st,bank-name = "GPIOE";
				status = "disabled";
			};

			gpiof: gpio@44290000 {
				gpio-controller;
				#gpio-cells = <2>;
				interrupt-controller;
				#interrupt-cells = <2>;
				#access-controller-cells = <1>;
				reg = <0x50000 0x400>;
				clocks = <&rcc CK_BUS_GPIOF>;
				st,bank-name = "GPIOF";
				status = "disabled";
			};

			gpiog: gpio@442a0000 {
				gpio-controller;
				#gpio-cells = <2>;
				interrupt-controller;
				#interrupt-cells = <2>;
				#access-controller-cells = <1>;
				reg = <0x60000 0x400>;
				clocks = <&rcc CK_BUS_GPIOG>;
				st,bank-name = "GPIOG";
				status = "disabled";
			};

			gpioh: gpio@442b0000 {
				gpio-controller;
				#gpio-cells = <2>;
				interrupt-controller;
				#interrupt-cells = <2>;
				#access-controller-cells = <1>;
				reg = <0x70000 0x400>;
				clocks = <&rcc CK_BUS_GPIOH>;
				st,bank-name = "GPIOH";
				status = "disabled";
			};

			gpioi: gpio@442c0000 {
				gpio-controller;
				#gpio-cells = <2>;
				interrupt-controller;
				#interrupt-cells = <2>;
				#access-controller-cells = <1>;
				reg = <0x80000 0x400>;
				clocks = <&rcc CK_BUS_GPIOI>;
				st,bank-name = "GPIOI";
				status = "disabled";
			};
		};

		exti2: interrupt-controller@442d0000 {
			compatible = "st,stm32mp1-exti", "syscon";
			interrupt-controller;
			#interrupt-cells = <2>;
			#address-cells = <0>;
			reg = <0x442d0000 0x400>;
			status = "disabled";
		};

		rtc: rtc@46000000 {
			compatible = "st,stm32mp25-rtc";
			reg = <0x46000000 0x400>;
			clocks = <&rcc CK_BUS_RTC>, <&rcc RTC_CK>;
			clock-names = "pclk", "rtc_ck";
			interrupts = <GIC_SPI 13 IRQ_TYPE_LEVEL_HIGH>;
		};

		tamp: tamp@46010000 {
			compatible = "st,stm32mp21-tamp";
			reg = <0x46010000 0x400>;
			clocks = <&rcc CK_BUS_RTC>;
			interrupts = <GIC_SPI 12 IRQ_TYPE_LEVEL_HIGH>;
			#address-cells = <1>;
			#size-cells = <1>;
			ranges;
			st,backup-zones = <24 24 24 24 12 12 8>;

			nvram: nvram@46010100 {
				compatible = "st,stm32mp25-tamp-nvram";
				#address-cells = <1>;
				#size-cells = <1>;
				reg = <0x46010100 0x200>;

				boot_mode: tamp-bkp@180 {
					reg = <0x180 0x4>;
				};
			};

			reboot_mode: reboot-mode {
				compatible = "nvmem-reboot-mode";
				nvmem-cells = <&boot_mode>;
				nvmem-cell-names = "reboot-mode";
				mode-normal = <0x00>;
				mode-fastboot = <0x01>;
				mode-recovery = <0x02>;
				mode-stm32cubeprogrammer = <0x03>;
				mode-ums_mmc0 = <0x10>;
				mode-ums_mmc1 = <0x11>;
				mode-ums_mmc2 = <0x12>;
				mode-romcode_serial = <0xff>;
			};
		};

		pinctrl_z: pinctrl@46200000 {
			#address-cells = <1>;
			#size-cells = <1>;
			compatible = "st,stm32mp215-z-pinctrl";
			ranges = <0 0x46200000 0x400>;

			gpioz: gpio@46200000 {
				gpio-controller;
				#gpio-cells = <2>;
				interrupt-controller;
				#interrupt-cells = <2>;
				#access-controller-cells = <1>;
				reg = <0 0x400>;
				clocks = <&rcc CK_BUS_GPIOZ>;
				st,bank-name = "GPIOZ";
				st,bank-ioport = <11>;
				status = "disabled";
			};
		};

		stgenc: stgen@48080000 {
			compatible = "st,stm32mp25-stgen";
			reg = <0x48080000 0x1000>;
			clocks = <&rcc CK_BUS_STGEN>, <&rcc CK_KER_STGEN>;
			clock-names = "bus", "tsgen_clk";
			st,tsgen-clk-source = <&rcc HSE_CK>;
		};

		fmc: memory-controller@48200000 {
			#address-cells = <2>;
			#size-cells = <1>;
			compatible = "st,stm32mp25-fmc2-ebi";
			reg = <0x48200000 0x400>;
			clocks = <&rcc CK_KER_FMC>;
			resets = <&rcc FMC_R>;
			status = "disabled";

			ranges = <0 0 0x60000000 0x04000000>, /* EBI CS 1 */
				 <1 0 0x64000000 0x04000000>, /* EBI CS 2 */
				 <2 0 0x68000000 0x04000000>, /* EBI CS 3 */
				 <3 0 0x6c000000 0x04000000>, /* EBI CS 4 */
				 <4 0 0x80000000 0x10000000>; /* NAND */
		};
	};

	soc1: soc@1 {
		compatible = "simple-bus";
		#address-cells = <1>;
		#size-cells = <1>;
		interrupt-parent = <&intc>;
		ranges = <0x0 0x0 0x0 0x80000000>;
	};
};
